# LPC1102_04 register map
File version: 4
CPU: CM0 r0p0, little endian, no MPU, no FPU, 0x2 interrupt priority bits, 0x0 interrupts
Registers are 32-bit, read-write, reset 0x0 unless marked. A register's access mark holds for its fields unless they carry their own. Offsets are from the block's base; [hi:lo] are bit positions; 'fields as' and 'values as' point back to an identical list.

## IOCON — I/O Configuration
Base 0x40044000
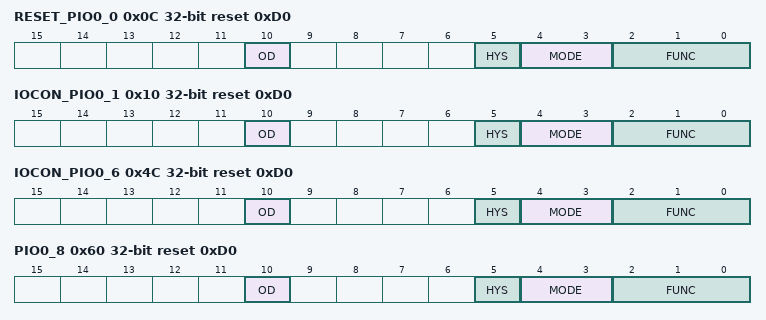
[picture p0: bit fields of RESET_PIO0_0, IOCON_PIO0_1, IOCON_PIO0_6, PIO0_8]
0x0C RESET_PIO0_0 reset 0xD0 — I/O configuration for pin RESET/PIO0_0
  [10] OD — Selects pseudo open-drain mode. See Section 7.1 for part specific details.
    0=STANDARD_GPIO_OUTPUT; 1=OPEN_DRAIN_OUTPUT
  [5] HYS — Hysteresis.
    0=DISABLE_; 1=ENABLE_
  [4:3] MODE — Selects function mode (on-chip pull-up/pull-down resistor control).
    0=INACTIVE_NO_PULL_DO (Inactive (no pull-down/pull-up resistor enabled).); 1=PULL_DOWN_RESISTOR_E (Pull-down resistor enabled.); 2=PULL_UP_RESISTOR_ENA (Pull-up resistor enabled.); 3=REPEATER_MODE_
  [2:0] FUNC — Selects pin function. All other values are reserved.
    0=SELECTS_FUNCTION_RESET; 1=SELECTS_FUNCTION_PIO0_0
0x10 IOCON_PIO0_1 reset 0xD0 — I/O configuration for pin PIO0_1/CLKOUT/CT32B0_MAT2
  [10] OD — Selects pseudo open-drain mode.
    0=STANDARD_GPIO_OUTPUT; 1=OPEN_DRAIN_OUTPUT
  [5] HYS — Hysteresis.
    0=DISABLE_; 1=ENABLE_
  [4:3] MODE — Selects function mode (on-chip pull-up/pull-down resistor control).
    values as RESET_PIO0_0.MODE
  [2:0] FUNC — Selects pin function. All other values are reserved.
    0=SELECTS_FUNCTION_PIO0_1; 1=SELECTS_FUNCTION_CLKOUT; 2=SELECTS_FUNCTION_CT32B0_MAT2
0x4C IOCON_PIO0_6 reset 0xD0 — I/O configuration for pin PIO0_6/SCK0
  [10] OD — Selects pseudo open-drain mode.
    0=STANDARD_GPIO_OUTPUT; 1=OPEN_DRAIN_OUTPUT
  [5] HYS — Hysteresis.
    0=DISABLE_; 1=ENABLE_
  [4:3] MODE — Selects function mode (on-chip pull-up/pull-down resistor control).
    values as RESET_PIO0_0.MODE
  [2:0] FUNC — Selects pin function. All other values are reserved.
    0=SELECTS_FUNCTION_PIO0_6; 2=SELECTS_FUNCTION_SCK0 (Selects function SCK0 (only if pin PIO0_6/SCK0 selected in Table 147).)
0x60 PIO0_8 reset 0xD0 — I/O configuration for pin PIO0_8/MISO0/CT16B0_MAT0
  [10] OD — Selects pseudo open-drain mode. See Section 7.1 for part specific details.
    0=STANDARD_GPIO_OUTPUT; 1=OPEN_DRAIN_OUTPUT
  [5] HYS — Hysteresis.
    0=DISABLE_; 1=ENABLE_
  [4:3] MODE — Selects function mode (on-chip pull-up/pull-down resistor control).
    values as RESET_PIO0_0.MODE
  [2:0] FUNC — Selects pin function. All other values are reserved.
    0=SELECTS_FUNCTION_PIO0_8; 1=SELECTS_FUNCTION_MISO0; 2=SELECTS_FUNCTION_CT16B0_MAT0
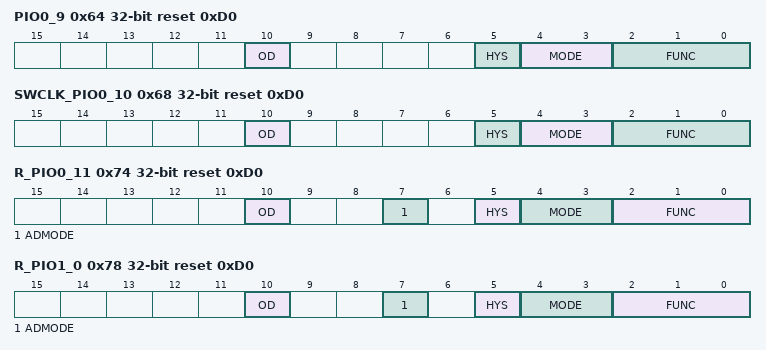
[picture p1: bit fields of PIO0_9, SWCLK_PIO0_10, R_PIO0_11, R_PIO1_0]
0x64 PIO0_9 reset 0xD0 — I/O configuration for pin PIO0_9/MOSI0/CT16B0_MAT1
  [10] OD — Selects pseudo open-drain mode. See Section 7.1 for part specific details.
    0=STANDARD_GPIO_OUTPUT; 1=OPEN_DRAIN_OUTPUT
  [5] HYS — Hysteresis.
    0=DISABLE_; 1=ENABLE_
  [4:3] MODE — Selects function mode (on-chip pull-up/pull-down resistor control).
    values as RESET_PIO0_0.MODE
  [2:0] FUNC — Selects pin function. All other values are reserved.
    0=SELECTS_FUNCTION_PIO0_9; 1=SELECTS_FUNCTION_MOSI0; 2=SELECTS_FUNCTION_CT16B0_MAT1
0x68 SWCLK_PIO0_10 reset 0xD0 — I/O configuration for pin SWCLK/PIO0_10/ SCK0/CT16B0_MAT2
  [10] OD — Selects pseudo open-drain mode.
    0=STANDARD_GPIO_OUTPUT; 1=OPEN_DRAIN_OUTPUT
  [5] HYS — Hysteresis.
    0=DISABLE_; 1=ENABLE_
  [4:3] MODE — Selects function mode (on-chip pull-up/pull-down resistor control).
    values as RESET_PIO0_0.MODE
  [2:0] FUNC — Selects pin function. All other values are reserved.
    0=SELECTS_FUNCTION_SWCLK; 1=SELECTS_FUNCTION_PIO0_10; 2=SELECTS_FUNCTION_SCK0 (Selects function SCK0 (only if pin SWCLK/PIO0_10/SCK0/CT16B0_MAT2 selected in Table 98).); 3=SELECTS_FUNCTION_CT16B0_MAT2
0x74 R_PIO0_11 reset 0xD0 — I/O configuration for pin R/PIO0_11/AD0/CT32B0_MAT3
  [10] OD — Selects pseudo open-drain mode.
    0=STANDARD_GPIO_OUTPUT; 1=OPEN_DRAIN_OUTPUT
  [7] ADMODE — Selects Analog/Digital mode
    0=ANALOG_INPUT_MODE; 1=DIGITAL_FUNCTIONAL_M (Digital functional mode)
  [5] HYS — Hysteresis.
    0=DISABLE_; 1=ENABLE_
  [4:3] MODE — Selects function mode (on-chip pull-up/pull-down resistor control).
    values as RESET_PIO0_0.MODE
  [2:0] FUNC — Selects pin function. All other values are reserved.
    0=SELECTS_FUNCTION_R_ (Selects function R. This function is reserved. Select one of the alternate functions below.); 1=SELECTS_FUNCTION_PIO0_11; 2=SELECTS_FUNCTION_AD0; 3=SELECTS_FUNCTION_CT32B0_MAT3
0x78 R_PIO1_0 reset 0xD0 — I/O configuration for pin R/PIO1_0/AD1/CT32B1_CAP0
  [10] OD — Selects pseudo open-drain mode. See Section 7.1 for part specific details.
    0=STANDARD_GPIO_OUTPUT; 1=OPEN_DRAIN_OUTPUT
  [7] ADMODE — Selects Analog/Digital mode
    values as R_PIO0_11.ADMODE
  [5] HYS — Hysteresis.
    0=DISABLE_; 1=ENABLE_
  [4:3] MODE — Selects function mode (on-chip pull-up/pull-down resistor control).
    values as RESET_PIO0_0.MODE
  [2:0] FUNC — Selects pin function. All other values are reserved.
    0=SELECTS_FUNCTION_R_ (Selects function R. This function is reserved. Select one of the alternate functions below.); 1=SELECTS_FUNCTION_PIO1_0; 2=SELECTS_FUNCTION_AD1; 3=SELECTS_FUNCTION_CT32B1_CAP0
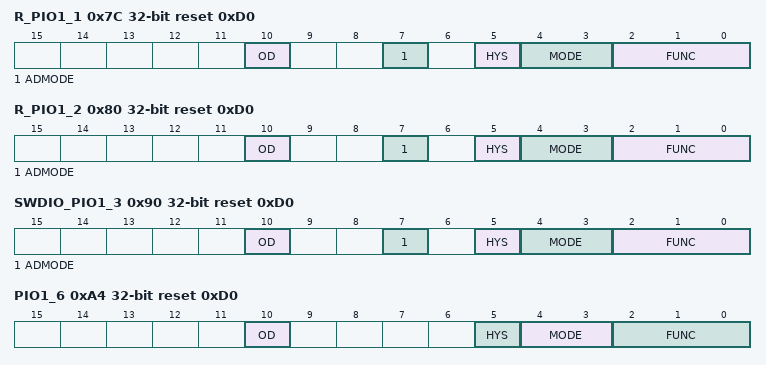
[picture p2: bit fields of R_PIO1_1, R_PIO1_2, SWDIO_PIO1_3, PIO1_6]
0x7C R_PIO1_1 reset 0xD0 — I/O configuration for pin R/PIO1_1/AD2/CT32B1_MAT0
  [10] OD — Selects pseudo open-drain mode. See Section 7.1 for part specific details.
    0=STANDARD_GPIO_OUTPUT; 1=OPEN_DRAIN_OUTPUT
  [7] ADMODE — Selects Analog/Digital mode
    values as R_PIO0_11.ADMODE
  [5] HYS — Hysteresis.
    0=DISABLE_; 1=ENABLE_
  [4:3] MODE — Selects function mode (on-chip pull-up/pull-down resistor control).
    values as RESET_PIO0_0.MODE
  [2:0] FUNC — Selects pin function. All other values are reserved.
    0=SELECTS_FUNCTION_R_ (Selects function R. This function is reserved. Select one of the alternate functions below.); 1=SELECTS_FUNCTION_PIO1_1; 2=SELECTS_FUNCTION_AD2; 3=SELECTS_FUNCTION_CT32B1_MAT0
0x80 R_PIO1_2 reset 0xD0 — I/O configuration for pin R/PIO1_2/AD3/CT32B1_MAT1
  [10] OD — Selects pseudo open-drain mode. See Section 7.1 for part specific details.
    0=STANDARD_GPIO_OUTPUT; 1=OPEN_DRAIN_OUTPUT
  [7] ADMODE — Selects Analog/Digital mode
    values as R_PIO0_11.ADMODE
  [5] HYS — Hysteresis.
    0=DISABLE_; 1=ENABLE_
  [4:3] MODE — Selects function mode (on-chip pull-up/pull-down resistor control).
    values as RESET_PIO0_0.MODE
  [2:0] FUNC — Selects pin function. All other values are reserved.
    0=SELECTS_FUNCTION_R_ (Selects function R. This function is reserved. Select one of the alternate functions below.); 1=SELECTS_FUNCTION_PIO1_2; 2=SELECTS_FUNCTION_AD3; 3=SELECTS_FUNCTION_CT32B1_MAT1
0x90 SWDIO_PIO1_3 reset 0xD0 — I/O configuration for pin SWDIO/PIO1_3/AD4/CT32B1_MAT2
  [10] OD — Selects pseudo open-drain mode.
    0=STANDARD_GPIO_OUTPUT; 1=OPEN_DRAIN_OUTPUT
  [7] ADMODE — Selects Analog/Digital mode
    values as R_PIO0_11.ADMODE
  [5] HYS — Hysteresis.
    0=DISABLE_; 1=ENABLE_
  [4:3] MODE — Selects function mode (on-chip pull-up/pull-down resistor control).
    values as RESET_PIO0_0.MODE
  [2:0] FUNC — Selects pin function. All other values are reserved.
    0=SELECTS_FUNCTION_SWDIO; 1=SELECTS_FUNCTION_PIO1_3; 2=SELECTS_FUNCTION_AD4; 3=SELECTS_FUNCTION_CT32B1_MAT2
0xA4 PIO1_6 reset 0xD0 — I/O configuration for pin PIO1_6/RXD/CT32B0_MAT0
  [10] OD — Selects pseudo open-drain mode. See Section 7.1 for part specific details.
    0=STANDARD_GPIO_OUTPUT; 1=OPEN_DRAIN_OUTPUT
  [5] HYS — Hysteresis.
    0=DISABLE_; 1=ENABLE_
  [4:3] MODE — Selects function mode (on-chip pull-up/pull-down resistor control).
    values as RESET_PIO0_0.MODE
  [2:0] FUNC — Selects pin function. All other values are reserved.
    0=SELECTS_FUNCTION_PIO1_6; 1=SELECTS_FUNCTION_RXD; 2=SELECTS_FUNCTION_CT32B0_MAT0
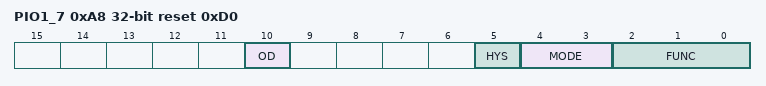
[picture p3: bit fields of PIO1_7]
0xA8 PIO1_7 reset 0xD0 — I/O configuration for pin PIO1_7/TXD/CT32B0_MAT1
  [10] OD — Selects pseudo open-drain mode. See Section 7.1 for part specific details.
    0=STANDARD_GPIO_OUTPUT; 1=OPEN_DRAIN_OUTPUT
  [5] HYS — Hysteresis.
    0=DISABLE_; 1=ENABLE_
  [4:3] MODE — Selects function mode (on-chip pull-up/pull-down resistor control).
    values as RESET_PIO0_0.MODE
  [2:0] FUNC — Selects pin function. All other values are reserved.
    0=SELECTS_FUNCTION_PIO1_7; 1=SELECTS_FUNCTION_TXD; 2=SELECTS_FUNCTION_CT32B0_MAT1
